# owm_reva register map
Registers are 32-bit, read-write, no defined reset value unless marked. A register's access mark holds for its fields unless they carry their own. Offsets are from the block's base; lines under a group give offsets from that group; [hi:lo] are bit positions; {n}, {i} and the like mark numbered series; 'fields as' and 'values as' point back to an identical list; <NAME> marks a mode.

## Memory map
0x4003D000 OWM size 0x1000 — 1-Wire Master Interface.

## Interrupts
67 OneWire (OWM)

## OWM — 1-Wire Master Interface.
Base 0x4003D000
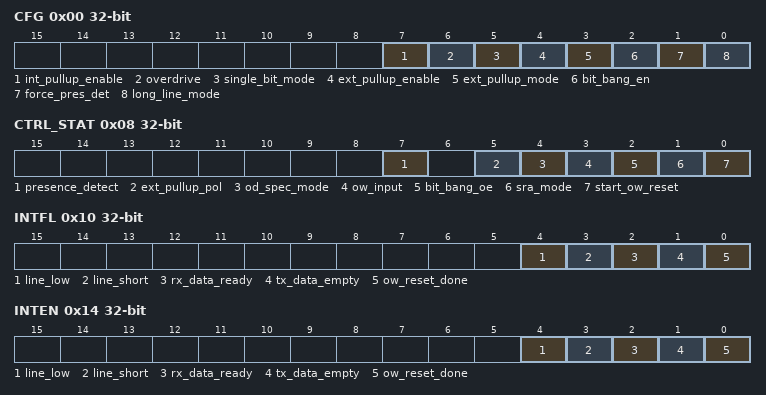
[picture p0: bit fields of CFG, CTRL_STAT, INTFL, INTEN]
0x00 CFG — 1-Wire Master Configuration.
  [7] int_pullup_enable — Enable intenral pullup.
  [6] overdrive — Enables overdrive speed for 1-Wire operations.
  [5] single_bit_mode — Enable Single Bit TX/RX Mode.
  [4] ext_pullup_enable — Enable External Pullup.
  [3] ext_pullup_mode — Provide an extra output control to control an external pullup.
  [2] bit_bang_en — Bit Bang Enable.
  [1] force_pres_det — Force Line During Presence Detect.
  [0] long_line_mode
0x04 CLK_DIV_1US — 1-Wire Master Clock Divisor.
  [7:0] divisor — Clock Divisor for 1Mhz.
0x08 CTRL_STAT — 1-Wire Master Control/Status.
  [7] presence_detect ro — Presence Pulse Detected.
  [5] ext_pullup_pol ro — External Pullup.
  [4] od_spec_mode ro — Overdrive Spec Mode.
  [3] ow_input ro — OW Input State.
  [2] bit_bang_oe — Bit Bang Output Enable.
  [1] sra_mode
  [0] start_ow_reset
0x0C DATA — 1-Wire Master Data Buffer.
  [7:0] tx_rx — TX/RX Buffer.
0x10 INTFL — 1-Wire Master Interrupt Flags.
  [4] line_low — OW Line Low Detected Interrupt Flag.
  [3] line_short — OW Line Short Detected Interrupt Flag.
  [2] rx_data_ready — RX Data Ready Interrupt Flag
  [1] tx_data_empty — TX Data Empty Interrupt Flag.
  [0] ow_reset_done — OW Reset Sequence Completed.
0x14 INTEN — 1-Wire Master Interrupt Enables.
  [4] line_low write-1-clears — OW Line Low Detected Interrupt Enable.
  [3] line_short write-1-clears — OW Line Short Detected Interrupt Enable.
  [2] rx_data_ready write-1-clears — Rx Data Ready Interrupt Enable.
  [1] tx_data_empty write-1-clears — Tx Data Empty Interrupt Enable.
  [0] ow_reset_done write-1-clears — OW Reset Sequence Completed.
